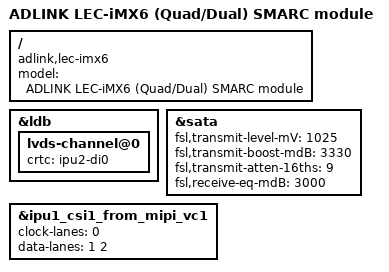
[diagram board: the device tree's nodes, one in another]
// SPDX-License-Identifier: GPL-2.0+
//
// Copyright 2014-2016 LiPPERT ADLINK Technology GmbH
// Copyright 2012 Freescale Semiconductor, Inc.
// Copyright 2011 Linaro Ltd.

/dts-v1/;

#include "imx6q.dtsi"
#include "lec-imx6.dtsi"

/ {
	model = "ADLINK LEC-iMX6 (Quad/Dual) SMARC module";
	compatible = "adlink,lec-imx6", "fsl,imx6q";
};

&ldb {
	lvds-channel@0 {
		crtc = "ipu2-di0";
	};
};

&sata {
	/* Freescale's defaults */
	fsl,transmit-level-mV = <1025>;
	fsl,transmit-boost-mdB = <3330>;
	fsl,transmit-atten-16ths = <9>;
	fsl,receive-eq-mdB = <3000>;
	status = "okay";
};

&ipu1_csi1_from_mipi_vc1 {
	clock-lanes = <0>;
	data-lanes = <1 2>;
};
